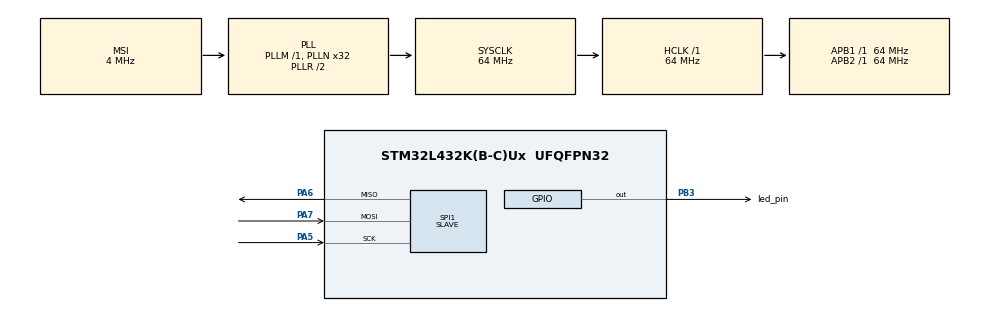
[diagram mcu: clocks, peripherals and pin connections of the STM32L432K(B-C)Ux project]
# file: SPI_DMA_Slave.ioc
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Dma.Request0=SPI1_RX
Dma.Request1=SPI1_TX
Dma.SPI1_RX.0.Direction=DMA_PERIPH_TO_MEMORY
Dma.SPI1_RX.0.Instance=DMA1_Channel2
Dma.SPI1_RX.0.MemDataAlignment=DMA_MDATAALIGN_BYTE
Dma.SPI1_RX.0.MemInc=DMA_MINC_ENABLE
Dma.SPI1_RX.0.Mode=DMA_NORMAL
Dma.SPI1_RX.0.PeriphDataAlignment=DMA_PDATAALIGN_BYTE
Dma.SPI1_RX.0.PeriphInc=DMA_PINC_DISABLE
Dma.SPI1_RX.0.Priority=DMA_PRIORITY_HIGH
Dma.SPI1_TX.1.Direction=DMA_MEMORY_TO_PERIPH
Dma.SPI1_TX.1.Instance=DMA1_Channel3
Dma.SPI1_TX.1.MemDataAlignment=DMA_MDATAALIGN_BYTE
Dma.SPI1_TX.1.MemInc=DMA_MINC_ENABLE
Dma.SPI1_TX.1.Mode=DMA_NORMAL
Dma.SPI1_TX.1.PeriphDataAlignment=DMA_PDATAALIGN_BYTE
Dma.SPI1_TX.1.PeriphInc=DMA_PINC_DISABLE
Dma.SPI1_TX.1.Priority=DMA_PRIORITY_HIGH
Mcu.Family=STM32L4
Mcu.Name=STM32L432K(B-C)Ux
Mcu.Package=UFQFPN32
NVIC.DMA1_Channel2_IRQn=true\:0\:0\:false\:false\:true\:false\:true
NVIC.DMA1_Channel3_IRQn=true\:0\:0\:false\:false\:true\:false\:true
NVIC.PriorityGroup=NVIC_PRIORITYGROUP_4
PA4.Signal=SPI1_NSS
PA5.Mode=Full_Duplex_Slave
PA5.Signal=SPI1_SCK
PA6.Mode=Full_Duplex_Slave
PA6.Signal=SPI1_MISO
PA7.Mode=Full_Duplex_Slave
PA7.Signal=SPI1_MOSI
PB3\ (JTDO-TRACESWO).GPIO_Label=led_pin
PB3\ (JTDO-TRACESWO).Signal=GPIO_Output
ProjectManager.HeapSize=0x200
ProjectManager.StackSize=0x400
ProjectManager.TargetToolchain=Makefile
RCC.AHBFreq_Value=64000000
RCC.APB1Freq_Value=64000000
RCC.APB1TimFreq_Value=64000000
RCC.APB2Freq_Value=64000000
RCC.APB2TimFreq_Value=64000000
RCC.CortexFreq_Value=64000000
RCC.HCLKFreq_Value=64000000
RCC.HSE_VALUE=8000000
RCC.HSI48_VALUE=48000000
RCC.HSI_VALUE=16000000
RCC.LSE_VALUE=32768
RCC.MSI_VALUE=4000000
RCC.PLLN=32
RCC.SYSCLKFreq_VALUE=64000000
RCC.SYSCLKSource=RCC_SYSCLKSOURCE_PLLCLK
RCC.VCOOutputFreq_Value=128000000
SPI1.DataSize=SPI_DATASIZE_8BIT
SPI1.Direction=SPI_DIRECTION_2LINES
SPI1.Mode=SPI_MODE_SLAVE
SPI1.VirtualType=VM_SLAVE
board=custom

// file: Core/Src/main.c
/* USER CODE BEGIN Header */
/**
 ******************************************************************************
 * @file           : main.c
 * @brief          : Main program body
 ******************************************************************************
 * @attention
 *
 * <h2><center>&copy; Copyright (c) 2021 STMicroelectronics.
 * All rights reserved.</center></h2>
 *
 * This software component is licensed by ST under BSD 3-Clause license,
 * the "License"; You may not use this file except in compliance with the
 * License. You may obtain a copy of the License at:
 *                        opensource.org/licenses/BSD-3-Clause
 *
 ******************************************************************************
 */
/* USER CODE END Header */
#include "main.h"
#include "dma.h"
#include "gpio.h"
#include "spi.h"

/* USER CODE BEGIN PV */
uint8_t tx_data[2] = {7, 4};
uint8_t rx_data[2] = {1, 2};
/* USER CODE END PV */

void SystemClock_Config(void);

int main(void) {

  /* MCU Configuration--------------------------------------------------------*/

  /* Reset of all peripherals, Initializes the Flash interface and the Systick.
   */
  HAL_Init();

  /* Configure the system clock */
  SystemClock_Config();

  /* Initialize all configured peripherals */
  MX_GPIO_Init();
  MX_DMA_Init();
  MX_SPI1_Init();

  /* Infinite loop */
  /* USER CODE BEGIN WHILE */
  while (1) {
    // HAL_GPIO_TogglePin(GPIOB, GPIO_PIN_3);
    // HAL_Delay(500);

    if (HAL_SPI_Receive_DMA(&hspi1, rx_data, sizeof(tx_data)) != HAL_OK) {
      /* Transfer error in transmission process */
      Error_Handler();
    }

    HAL_Delay(1);
    /* USER CODE END WHILE */

  }
}

void SystemClock_Config(void) {
  RCC_OscInitTypeDef RCC_OscInitStruct = {0};
  RCC_ClkInitTypeDef RCC_ClkInitStruct = {0};

  /** Configure the main internal regulator output voltage
   */
  if (HAL_PWREx_ControlVoltageScaling(PWR_REGULATOR_VOLTAGE_SCALE1) != HAL_OK) {
    Error_Handler();
  }
  /** Initializes the RCC Oscillators according to the specified parameters
   * in the RCC_OscInitTypeDef structure.
   */
  RCC_OscInitStruct.OscillatorType = RCC_OSCILLATORTYPE_MSI;
  RCC_OscInitStruct.MSIState = RCC_MSI_ON;
  RCC_OscInitStruct.MSICalibrationValue = 0;
  RCC_OscInitStruct.MSIClockRange = RCC_MSIRANGE_6;
  RCC_OscInitStruct.PLL.PLLState = RCC_PLL_ON;
  RCC_OscInitStruct.PLL.PLLSource = RCC_PLLSOURCE_MSI;
  RCC_OscInitStruct.PLL.PLLM = 1;
  RCC_OscInitStruct.PLL.PLLN = 32;
  RCC_OscInitStruct.PLL.PLLP = RCC_PLLP_DIV7;
  RCC_OscInitStruct.PLL.PLLQ = RCC_PLLQ_DIV2;
  RCC_OscInitStruct.PLL.PLLR = RCC_PLLR_DIV2;
  if (HAL_RCC_OscConfig(&RCC_OscInitStruct) != HAL_OK) {
    Error_Handler();
  }
  /** Initializes the CPU, AHB and APB buses clocks
   */
  RCC_ClkInitStruct.ClockType = RCC_CLOCKTYPE_HCLK | RCC_CLOCKTYPE_SYSCLK |
                                RCC_CLOCKTYPE_PCLK1 | RCC_CLOCKTYPE_PCLK2;
  RCC_ClkInitStruct.SYSCLKSource = RCC_SYSCLKSOURCE_PLLCLK;
  RCC_ClkInitStruct.AHBCLKDivider = RCC_SYSCLK_DIV1;
  RCC_ClkInitStruct.APB1CLKDivider = RCC_HCLK_DIV1;
  RCC_ClkInitStruct.APB2CLKDivider = RCC_HCLK_DIV1;

  if (HAL_RCC_ClockConfig(&RCC_ClkInitStruct, FLASH_LATENCY_3) != HAL_OK) {
    Error_Handler();
  }
}

/* USER CODE BEGIN 4 */
// void HAL_SPI_RxCpltCallback(SPI_HandleTypeDef *hspi) {
//   /* Turn LED3 on: Transfer in transmission/reception process is complete */
//   HAL_GPIO_TogglePin(GPIOB, GPIO_PIN_3);
//   // HAL_GPIO_WritePin(GPIOA, GPIO_PIN_4, GPIO_PIN_SET);
// }
/* USER CODE END 4 */

void Error_Handler(void) {
  __disable_irq();
  while (1) {
  }
}

#ifdef USE_FULL_ASSERT
/**
 * @brief  Reports the name of the source file and the source line number
 *         where the assert_param error has occurred.
 * @param  file: pointer to the source file name
 * @param  line: assert_param error line source number
 * @retval None
 */
void assert_failed(uint8_t *file, uint32_t line) {
  /* USER CODE BEGIN 6 */
  /* User can add his own implementation to report the file name and line
     number,
     ex: printf("Wrong parameters value: file %s on line %d\r\n", file, line) */
  /* USER CODE END 6 */
}
#endif /* USE_FULL_ASSERT */

/************************ (C) COPYRIGHT STMicroelectronics *****END OF FILE****/
